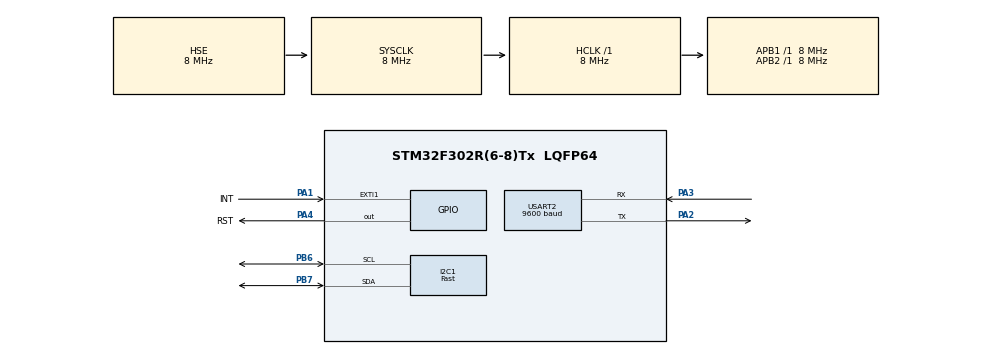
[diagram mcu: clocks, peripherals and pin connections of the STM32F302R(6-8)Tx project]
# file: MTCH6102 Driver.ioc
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I2C1.I2C_Speed_Mode=I2C_Fast
I2C1.Timing=0x0010020A
Mcu.Family=STM32F3
Mcu.Name=STM32F302R(6-8)Tx
Mcu.Package=LQFP64
NVIC.EXTI1_IRQn=true\:0\:0\:false\:false\:true\:true\:true\:true
NVIC.PriorityGroup=NVIC_PRIORITYGROUP_4
PA1.GPIO_Label=INT
PA1.Signal=GPXTI1
PA13.Mode=Serial_Wire
PA13.Signal=SYS_JTMS-SWDIO
PA14.Mode=Serial_Wire
PA14.Signal=SYS_JTCK-SWCLK
PA2.Mode=Asynchronous
PA2.Signal=USART2_TX
PA3.Mode=Asynchronous
PA3.Signal=USART2_RX
PA4.GPIO_Label=RST
PA4.GPIO_PuPd=GPIO_PULLUP
PA4.Signal=GPIO_Output
PB6.GPIO_Pu=GPIO_NOPULL
PB6.Mode=I2C
PB6.Signal=I2C1_SCL
PB7.GPIO_Pu=GPIO_NOPULL
PB7.Mode=I2C
PB7.Signal=I2C1_SDA
PF0-OSC_IN.Mode=HSE-External-Oscillator
PF0-OSC_IN.Signal=RCC_OSC_IN
PF1-OSC_OUT.Mode=HSE-External-Oscillator
PF1-OSC_OUT.Signal=RCC_OSC_OUT
ProjectManager.HeapSize=0x200
ProjectManager.StackSize=0x400
ProjectManager.TargetToolchain=STM32CubeIDE
RCC.AHBFreq_Value=8000000
RCC.APB1Freq_Value=8000000
RCC.APB1TimFreq_Value=8000000
RCC.APB2Freq_Value=8000000
RCC.APB2TimFreq_Value=8000000
RCC.CortexFreq_Value=8000000
RCC.HCLKFreq_Value=8000000
RCC.HSE_VALUE=8000000
RCC.HSI_VALUE=8000000
RCC.LSE_VALUE=32768
RCC.PLLSourceVirtual=RCC_PLLSOURCE_HSE
RCC.SYSCLKFreq_VALUE=8000000
RCC.SYSCLKSourceVirtual=RCC_SYSCLKSOURCE_HSE
RCC.USBFreq_Value=16000000
USART2.BaudRate=9600
USART2.VirtualMode-Asynchronous=VM_ASYNC
board=custom

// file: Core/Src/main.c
/* USER CODE BEGIN Header */
/**
  ******************************************************************************
  * @file           : main.c
  * @brief          : Main program body
  ******************************************************************************
  * @attention
  *
  * Copyright (c) 2026 STMicroelectronics.
  * All rights reserved.
  *
  * This software is licensed under terms that can be found in the LICENSE file
  * in the root directory of this software component.
  * If no LICENSE file comes with this software, it is provided AS-IS.
  *
  ******************************************************************************
  */
/* USER CODE END Header */
#include "main.h"

/* USER CODE BEGIN Includes */
#include "stdio.h"

#include "MTCH6102.h"
/* USER CODE END Includes */

I2C_HandleTypeDef hi2c1;

UART_HandleTypeDef huart2;

/* USER CODE BEGIN PV */
mtch6102_t mtch6102;
/* USER CODE END PV */

void SystemClock_Config(void);
static void MX_GPIO_Init(void);
static void MX_I2C1_Init(void);
static void MX_USART2_UART_Init(void);

int main(void)
{

  /* MCU Configuration--------------------------------------------------------*/

  /* Reset of all peripherals, Initializes the Flash interface and the Systick. */
  HAL_Init();

  /* Configure the system clock */
  SystemClock_Config();

  /* Initialize all configured peripherals */
  MX_GPIO_Init();
  MX_I2C1_Init();
  MX_USART2_UART_Init();
  /* USER CODE BEGIN 2 */
  MTCH6102_Init (&mtch6102, &hi2c1);

  /* USER CODE END 2 */

  /* Infinite loop */
  while (1)
  {

  }
}

void SystemClock_Config(void)
{
  RCC_OscInitTypeDef RCC_OscInitStruct = {0};
  RCC_ClkInitTypeDef RCC_ClkInitStruct = {0};
  RCC_PeriphCLKInitTypeDef PeriphClkInit = {0};

  /** Initializes the RCC Oscillators according to the specified parameters
  * in the RCC_OscInitTypeDef structure.
  */
  RCC_OscInitStruct.OscillatorType = RCC_OSCILLATORTYPE_HSI|RCC_OSCILLATORTYPE_HSE;
  RCC_OscInitStruct.HSEState = RCC_HSE_ON;
  RCC_OscInitStruct.HSIState = RCC_HSI_ON;
  RCC_OscInitStruct.HSICalibrationValue = RCC_HSICALIBRATION_DEFAULT;
  RCC_OscInitStruct.PLL.PLLState = RCC_PLL_NONE;
  if (HAL_RCC_OscConfig(&RCC_OscInitStruct) != HAL_OK)
  {
    Error_Handler();
  }

  /** Initializes the CPU, AHB and APB buses clocks
  */
  RCC_ClkInitStruct.ClockType = RCC_CLOCKTYPE_HCLK|RCC_CLOCKTYPE_SYSCLK
                              |RCC_CLOCKTYPE_PCLK1|RCC_CLOCKTYPE_PCLK2;
  RCC_ClkInitStruct.SYSCLKSource = RCC_SYSCLKSOURCE_HSE;
  RCC_ClkInitStruct.AHBCLKDivider = RCC_SYSCLK_DIV1;
  RCC_ClkInitStruct.APB1CLKDivider = RCC_HCLK_DIV1;
  RCC_ClkInitStruct.APB2CLKDivider = RCC_HCLK_DIV1;

  if (HAL_RCC_ClockConfig(&RCC_ClkInitStruct, FLASH_LATENCY_0) != HAL_OK)
  {
    Error_Handler();
  }
  PeriphClkInit.PeriphClockSelection = RCC_PERIPHCLK_I2C1;
  PeriphClkInit.I2c1ClockSelection = RCC_I2C1CLKSOURCE_HSI;
  if (HAL_RCCEx_PeriphCLKConfig(&PeriphClkInit) != HAL_OK)
  {
    Error_Handler();
  }
}

static void MX_I2C1_Init(void)
{

  hi2c1.Instance = I2C1;
  hi2c1.Init.Timing = 0x0010020A;
  hi2c1.Init.OwnAddress1 = 0;
  hi2c1.Init.AddressingMode = I2C_ADDRESSINGMODE_7BIT;
  hi2c1.Init.DualAddressMode = I2C_DUALADDRESS_DISABLE;
  hi2c1.Init.OwnAddress2 = 0;
  hi2c1.Init.OwnAddress2Masks = I2C_OA2_NOMASK;
  hi2c1.Init.GeneralCallMode = I2C_GENERALCALL_DISABLE;
  hi2c1.Init.NoStretchMode = I2C_NOSTRETCH_DISABLE;
  if (HAL_I2C_Init(&hi2c1) != HAL_OK)
  {
    Error_Handler();
  }

  /** Configure Analogue filter
  */
  if (HAL_I2CEx_ConfigAnalogFilter(&hi2c1, I2C_ANALOGFILTER_ENABLE) != HAL_OK)
  {
    Error_Handler();
  }

  /** Configure Digital filter
  */
  if (HAL_I2CEx_ConfigDigitalFilter(&hi2c1, 0) != HAL_OK)
  {
    Error_Handler();
  }

}

static void MX_USART2_UART_Init(void)
{

  huart2.Instance = USART2;
  huart2.Init.BaudRate = 9600;
  huart2.Init.WordLength = UART_WORDLENGTH_8B;
  huart2.Init.StopBits = UART_STOPBITS_1;
  huart2.Init.Parity = UART_PARITY_NONE;
  huart2.Init.Mode = UART_MODE_TX_RX;
  huart2.Init.HwFlowCtl = UART_HWCONTROL_NONE;
  huart2.Init.OverSampling = UART_OVERSAMPLING_16;
  huart2.Init.OneBitSampling = UART_ONE_BIT_SAMPLE_DISABLE;
  huart2.AdvancedInit.AdvFeatureInit = UART_ADVFEATURE_NO_INIT;
  if (HAL_UART_Init(&huart2) != HAL_OK)
  {
    Error_Handler();
  }

}

static void MX_GPIO_Init(void)
{
  GPIO_InitTypeDef GPIO_InitStruct = {0};

  /* GPIO Ports Clock Enable */
  __HAL_RCC_GPIOF_CLK_ENABLE();
  __HAL_RCC_GPIOA_CLK_ENABLE();
  __HAL_RCC_GPIOB_CLK_ENABLE();

  /*Configure GPIO pin Output Level */
  HAL_GPIO_WritePin(RST_GPIO_Port, RST_Pin, GPIO_PIN_RESET);

  /*Configure GPIO pin : INT_Pin */
  GPIO_InitStruct.Pin = INT_Pin;
  GPIO_InitStruct.Mode = GPIO_MODE_IT_RISING;
  GPIO_InitStruct.Pull = GPIO_NOPULL;
  HAL_GPIO_Init(INT_GPIO_Port, &GPIO_InitStruct);

  /*Configure GPIO pin : RST_Pin */
  GPIO_InitStruct.Pin = RST_Pin;
  GPIO_InitStruct.Mode = GPIO_MODE_OUTPUT_PP;
  GPIO_InitStruct.Pull = GPIO_PULLUP;
  GPIO_InitStruct.Speed = GPIO_SPEED_FREQ_LOW;
  HAL_GPIO_Init(RST_GPIO_Port, &GPIO_InitStruct);

  /* EXTI interrupt init*/
  HAL_NVIC_SetPriority(EXTI1_IRQn, 0, 0);
  HAL_NVIC_EnableIRQ(EXTI1_IRQn);

}

void Error_Handler(void)
{
  __disable_irq();
  while (1)
  {
  }
}
